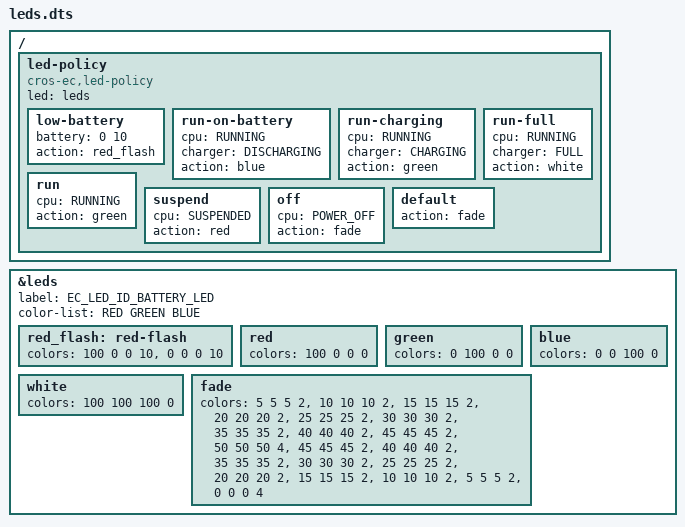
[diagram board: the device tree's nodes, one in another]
/* Copyright 2022 The Chromium OS Authors. All rights reserved.
 * Use of this source code is governed by a BSD-style license that can be
 * found in the LICENSE file.
 */

#include <dt-bindings/colors.h>

/ {
	/*
	 * Mapping of inputs to LED actions
	 */
	led-policy {
		compatible = "cros-ec,led-policy";

		led = <&leds>;

		low-battery {
			battery = <0 10>;
			action = <&red_flash>;
		};
		run-on-battery {
			cpu = "RUNNING";
			charger = "DISCHARGING";
			action = <&blue>;
		};
		run-charging {
			cpu = "RUNNING";
			charger = "CHARGING";
			action = <&green>;
		};
		run-full {
			cpu = "RUNNING";
			charger = "FULL";
			action = <&white>;
		};
		run {
			cpu = "RUNNING";
			action = <&green>;
		};
		suspend {
			cpu = "SUSPENDED";
			action = <&red>;
		};
		off {
			cpu = "POWER_OFF";
			action = <&fade>;
		};
		default {
			action = <&fade>;
		};
	};
};

&leds {
	label = "EC_LED_ID_BATTERY_LED";
	color-list = <RED GREEN BLUE>;
	/*
	 * LED colours and actions
	 * Values are R G B Duration.
	 * Duration is in tenths of a second.
	 */
	red_flash: red-flash {
		colors = <100 0 0 10>,
			 <0 0 0 10>;
	};
	red: red {
		colors = <100 0 0 0>;
	};
	green: green {
		colors = <0 100 0 0>;
	};
	blue: blue {
		colors = <0 0 100 0>;
	};
	white: white {
		colors = <100 100 100 0>;
	};
	fade: fade {
		colors = <5 5 5 2>, <10 10 10 2>, <15 15 15 2>,
			<20 20 20 2>, <25 25 25 2>, <30 30 30 2>,
			<35 35 35 2>, <40 40 40 2>, <45 45 45 2>,
			<50 50 50 4>,
			<45 45 45 2>, <40 40 40 2>, <35 35 35 2>,
			<30 30 30 2>, <25 25 25 2>, <20 20 20 2>,
			<15 15 15 2>, <10 10 10 2>, <5 5 5 2>,
			<0 0 0 4>;
	};
};
